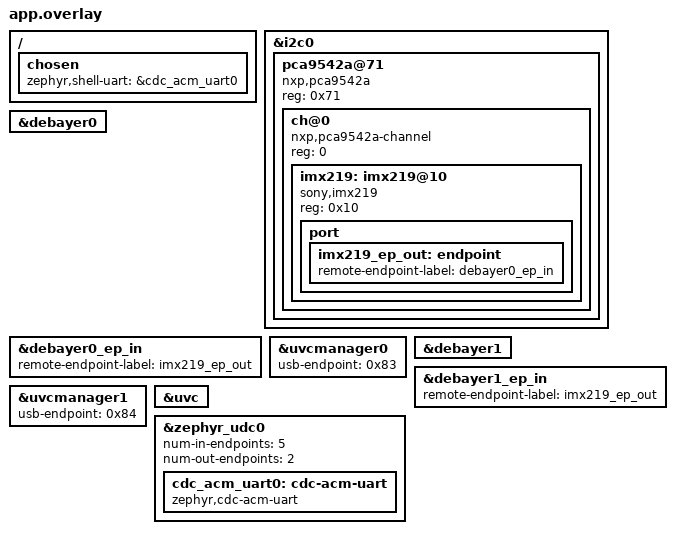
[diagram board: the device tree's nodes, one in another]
/*
 * Copyright (c) 2024 tinyVision.ai Inc.
 *
 * SPDX-License-Identifier: Apache-2.0
 */

/ {
	chosen {
		zephyr,shell-uart = &cdc_acm_uart0;
	};
};

&i2c0 {
	status = "okay";

	pca9542a@71 {
		compatible = "nxp,pca9542a";
		reg = <0x71>;
		#address-cells = <1>;
		#size-cells = <0>;

		ch@0 {
			compatible = "nxp,pca9542a-channel";
			reg = <0>;
			#address-cells = <1>;
			#size-cells = <0>;

			imx219: imx219@10 {
				compatible = "sony,imx219";
				reg = <0x10>;

				port {
					imx219_ep_out: endpoint {
						remote-endpoint-label = "debayer0_ep_in";
					};
				};
			};
		};
	};
};

&debayer0 {
	status = "okay";
};

&debayer0_ep_in {
	remote-endpoint-label = "imx219_ep_out";
};

&uvcmanager0 {
	status = "okay";

	/* From UVC's "bEndpointAddress" in "lsusb -v -d 1209:0001" output */
	usb-endpoint = <0x83>;
};

&debayer1 {
	status = "okay";
};

&debayer1_ep_in {
	remote-endpoint-label = "imx219_ep_out";
};

&uvcmanager1 {
	status = "okay";

	/* From UVC's "bEndpointAddress" in "lsusb -v -d 1209:0001" output */
	usb-endpoint = <0x84>;
};

&uvc {
	status = "okay";
};

&zephyr_udc0 {
	num-in-endpoints = <5>;
	num-out-endpoints = <2>;
	status = "okay";

	cdc_acm_uart0: cdc-acm-uart {
		compatible = "zephyr,cdc-acm-uart";
	};
};
